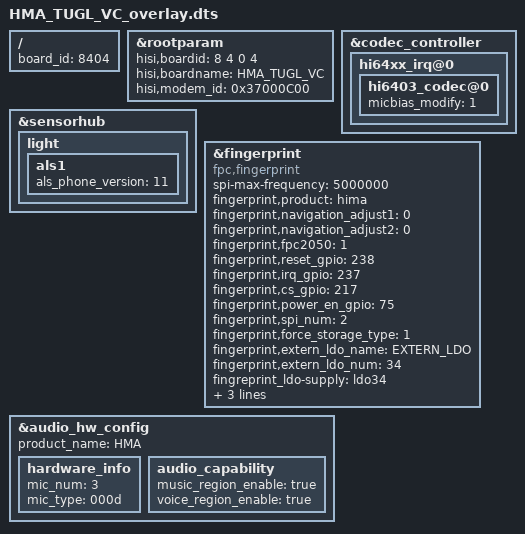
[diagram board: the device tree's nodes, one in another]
/**
 * Copyright (C) 2014 Hisilicon Ltd.
 *
 *  This program is free software; you can redistribute it and/or modify
 *  it under the terms of the GNU General Public License version 2 as
 *  publishhed by the Free Software Foundation.
 */

/dts-v1/;
/plugin/;
/include/ "HMA_TUGL_VB_overlay.dtsi"
/include/ "HMA_TUGL_VC_pin.dtsi"
/include/ "HMA_TUGL_VC_modem_pin.dtsi"

/ {
    board_id = <8404>;
};

	&rootparam{
		hisi,boardid = <8 4 0 4>;
		hisi,boardname = "HMA_TUGL_VC";
		hisi,modem_id = <0x37000C00>;
	};

	/* audio device beg */
	&codec_controller {
		hi64xx_irq@0 {
			hi6403_codec@0 {
				micbias_modify = <1>; //MICBIAS output 2.7V factory test, change from MAINMIC to MIC4.
			};
		};
	};

	&sensorhub{
		light{
			als1{
				als_phone_version = <11>;
			};
		};
	};

	&fingerprint {
		compatible = "fpc,fingerprint";
		spi-max-frequency = <5000000>;
		fingerprint,product = "hima";

		fingerprint,navigation_adjust1 = <0>;
		fingerprint,navigation_adjust2 = <0>;

		fingerprint,fpc2050 = <1>;
		fingerprint,reset_gpio = <238>;
		fingerprint,irq_gpio = <237>;
		fingerprint,cs_gpio = <217>;
		fingerprint,power_en_gpio = <75>;
		fingerprint,spi_num = <2>;
		fingerprint,force_storage_type = <1>;
		fingerprint,extern_ldo_name = "EXTERN_LDO";
		fingerprint,extern_ldo_num = <34>;
		fingreprint_ldo-supply = <&ldo34>;
		fingerprint,extern_vol = <3300000>;
		fingerprint,custom_timing_scheme = <3>; /*1:vdd->1ms->rst/cs; 2:vdd->10ms->rst/cs; 3:vdd->10ms->cs->600us->rst; 4:vdd->rst1/cs1/rst/cs0*/
		fingerprint,poweroff_scheme = <2>; /*1:close ldo ;2:close loadswitch(gpio)*/
	};

	&audio_hw_config {
		product_name = "HMA";
		hardware_info {
			mic_num = "3";
			mic_type = "000d";/*0001 deputy mic   0002 main mic   0004 deputy mic2   0008 main mic2*/
			status = "ok";
		};
		audio_capability {
			music_region_enable = "true";
			voice_region_enable = "true";
		};
	};
